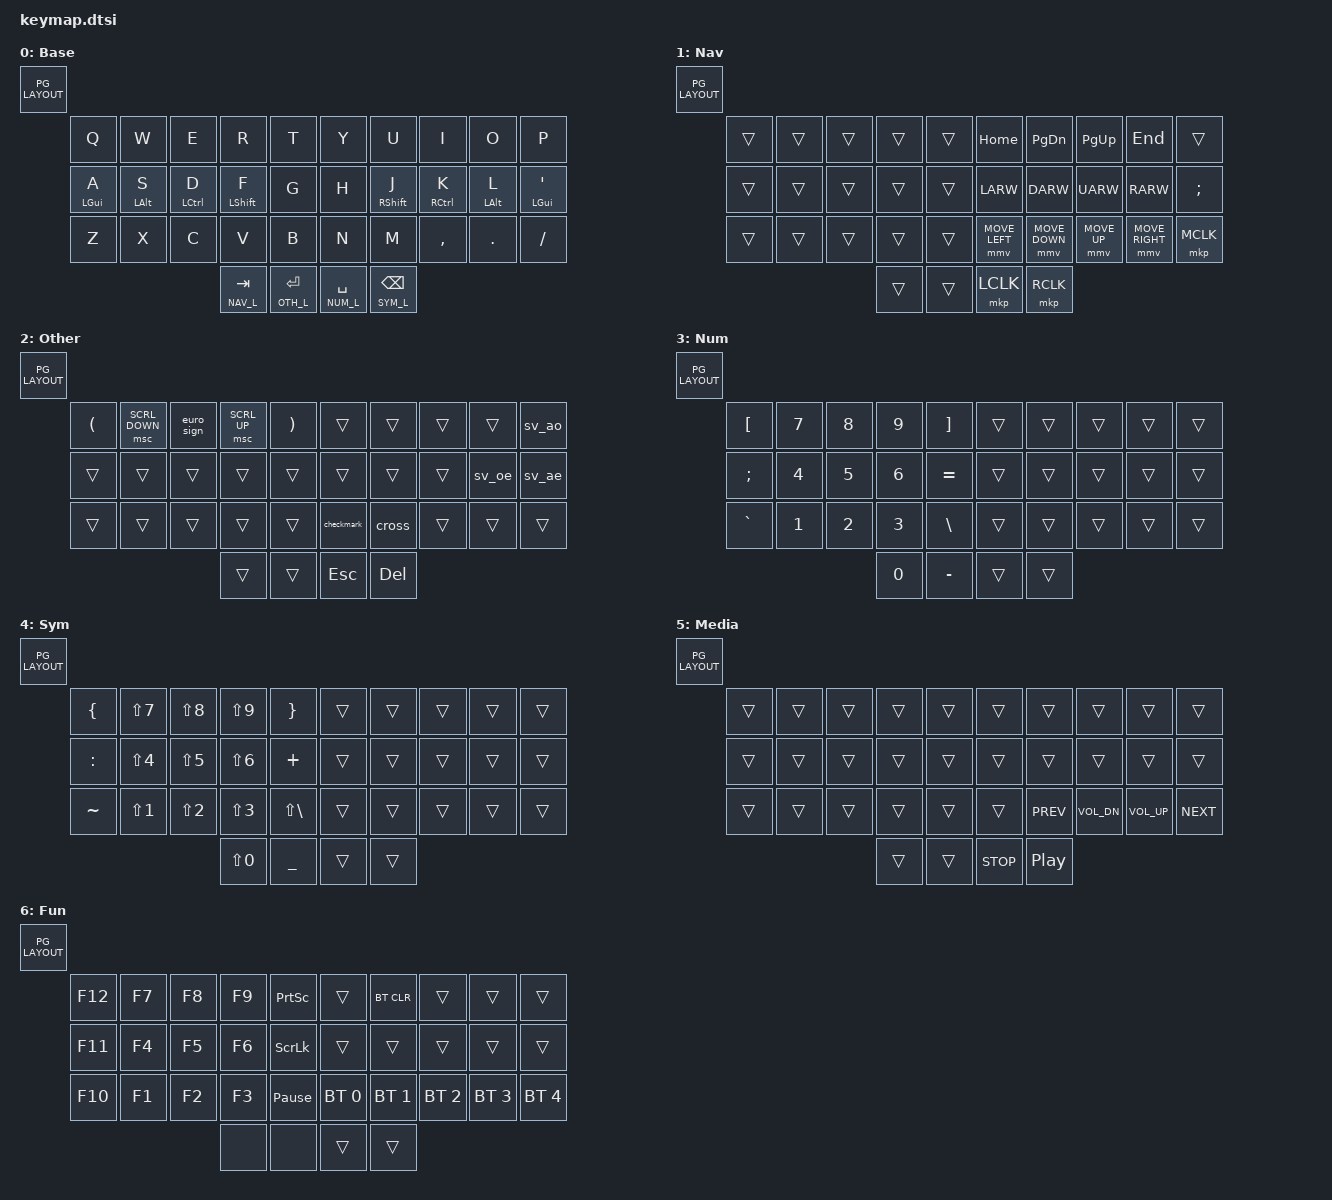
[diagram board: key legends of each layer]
/*
 * Generic 34-key split keyboard keymap: layers (Base/Nav/Other/Num/Sym/Media/
 * Fun), home-row mods, thumb combos, and custom Unicode chars, bundled into a
 * single include.
 *
 * Each layer is written as 34 logical keys (5 columns x 3 rows per side, then
 * thumbs LH1 LH0 RH0 RH1) passed to PG_LAYOUT(...), which expands them into
 * the board's physical `bindings` order. The default layout is the plain
 * 34-key one; boards with more keys select theirs before including this file
 * (see layout.h), e.g. "petergil-zmk-keymap/layouts/kyria.h".
 *
 * Prerequisites (include before this file, at the top of the board's
 * .keymap, in the usual ZMK order):
 *   - <behaviors.dtsi>, <dt-bindings/zmk/keys.h>, <dt-bindings/zmk/bt.h>
 *   - <dt-bindings/zmk/pointing.h>, plus CONFIG_ZMK_POINTING=y in the
 *     board/shield .conf (provides &mmv, &mkp, &msc)
 *   - `#define HOST_OS <n>` (see zmk-helpers' README for values)
 *   - optionally, a non-default layout header (see layout.h)
 *
 * Everything else, including zmk-helpers itself, is pulled in automatically.
 */

#include "petergil-zmk-keymap/layout.h"
#include "petergil-zmk-keymap/layers.h"
#include "petergil-zmk-keymap/behaviors.dtsi"
#include "petergil-zmk-keymap/chars.dtsi"
#include "petergil-zmk-keymap/combos.dtsi"

/ {
    keymap {
        compatible = "zmk,keymap";

        /* LT4 LT3 LT2 LT1 LT0   RT0 RT1 RT2 RT3 RT4 */
        /* LM4 LM3 LM2 LM1 LM0   RM0 RM1 RM2 RM3 RM4 */
        /* LB4 LB3 LB2 LB1 LB0   RB0 RB1 RB2 RB3 RB4 */
        /*             LH1 LH0   RH0 RH1             */

        default_layer {
            label = "Base";
            bindings = <PG_LAYOUT(
                &kp Q,      &kp W,      &kp E,       &kp R,          &kp T,         &kp Y,            &kp U,          &kp I,       &kp O,      &kp P,
                &hm LGUI A, &hm LALT S, &hm LCTRL D, &hm LSHFT F,    &kp G,         &kp H,            &hm RSHFT J,    &hm RCTRL K, &hm LALT L, &hm LGUI QUOT,
                &kp Z,      &kp X,      &kp C,       &kp V,          &kp B,         &kp N,            &kp M,          &kp COMMA,   &kp DOT,    &kp FSLH,
                                                     &lt NAV_L TAB,  &lt OTH_L RET, &lt NUM_L SPACE,  &lt SYM_L BKSP
            )>;
        };

        nav_layer {
            label = "Nav";
            bindings = <PG_LAYOUT(
                &trans,     &trans,     &trans,      &trans,          &trans,       &kp HOME,       &kp PG_DN,      &kp PG_UP,    &kp END,         &trans,
                &trans,     &trans,     &trans,      &trans,          &trans,       &kp LARW,       &kp DARW,       &kp UARW,     &kp RARW,        &kp SEMI,
                &trans,     &trans,     &trans,      &trans,          &trans,       &mmv MOVE_LEFT, &mmv MOVE_DOWN, &mmv MOVE_UP, &mmv MOVE_RIGHT, &mkp MCLK,
                                                     &trans,          &trans,       &mkp LCLK,      &mkp RCLK
            )>;
        };

        other_layer {
            label = "Other";
            bindings = <PG_LAYOUT(
                &kp LPAR,   &msc SCRL_DOWN, &euro_sign,  &msc SCRL_UP,    &kp RPAR,     &trans,           &trans,        &trans,       &trans,     &sv_ao,
                &trans,     &trans,         &trans,      &trans,          &trans,       &trans,           &trans,        &trans,       &sv_oe,     &sv_ae,
                &trans,     &trans,         &trans,      &trans,          &trans,       &checkmark,       &cross,        &trans,       &trans,     &trans,
                                                         &trans,          &trans,       &kp ESC,          &kp DEL
            )>;
        };

        num_layer {
            label = "Num";
            bindings = <PG_LAYOUT(
                &kp LBKT,   &kp N7,     &kp N8,      &kp N9,          &kp RBKT,      &trans,          &trans,         &trans,      &trans,     &trans,
                &kp SEMI,   &kp N4,     &kp N5,      &kp N6,          &kp EQUAL,     &trans,          &trans,         &trans,      &trans,     &trans,
                &kp GRAVE,  &kp N1,     &kp N2,      &kp N3,          &kp BSLH,      &trans,          &trans,         &trans,      &trans,     &trans,
                                                     &kp N0,          &kp MINUS,     &trans,          &trans
            )>;
        };

        sym_layer {
            label = "Sym";
            bindings = <PG_LAYOUT(
                &kp LBRC,     &kp LS(N7),  &kp LS(N8),  &kp LS(N9), &kp RBRC,        &trans, &trans,   &trans,    &trans,    &trans,
                &kp COLON,    &kp LS(N4),  &kp LS(N5),  &kp LS(N6), &kp PLUS,        &trans, &trans,   &trans,    &trans,    &trans,
                &kp TILDE,    &kp LS(N1),  &kp LS(N2),  &kp LS(N3), &kp LS(BSLH),    &trans, &trans,   &trans,    &trans,    &trans,
                                                        &kp LS(N0), &kp UNDER,       &trans, &trans
            )>;
        };

        media_layer {
            label = "Media";
            bindings = <PG_LAYOUT(
                &trans,     &trans,     &trans,      &trans,          &trans,       &trans,           &trans,         &trans,       &trans,       &trans,
                &trans,     &trans,     &trans,      &trans,          &trans,       &trans,           &trans,         &trans,       &trans,       &trans,
                &trans,     &trans,     &trans,      &trans,          &trans,       &trans,           &kp C_PREV,     &kp C_VOL_DN, &kp C_VOL_UP, &kp C_NEXT,
                                                     &trans,          &trans,       &kp C_STOP,       &kp C_PLAY_PAUSE
            )>;
        };

        fun_layer {
            label = "Fun";
            bindings = <PG_LAYOUT(
                &kp F12,     &kp F7,     &kp F8,      &kp F9,     &kp PSCRN,         &trans,          &bt BT_CLR,     &trans,       &trans,       &trans,
                &kp F11,     &kp F4,     &kp F5,      &kp F6,     &kp SLCK,          &trans,          &trans,         &trans,       &trans,       &trans,
                &kp F10,     &kp F1,     &kp F2,      &kp F3,     &kp PAUSE_BREAK,   &bt BT_SEL 0,    &bt BT_SEL 1,   &bt BT_SEL 2, &bt BT_SEL 3, &bt BT_SEL 4,
                                                      &none,      &none,             &trans,          &trans
            )>;
        };
    };
};
